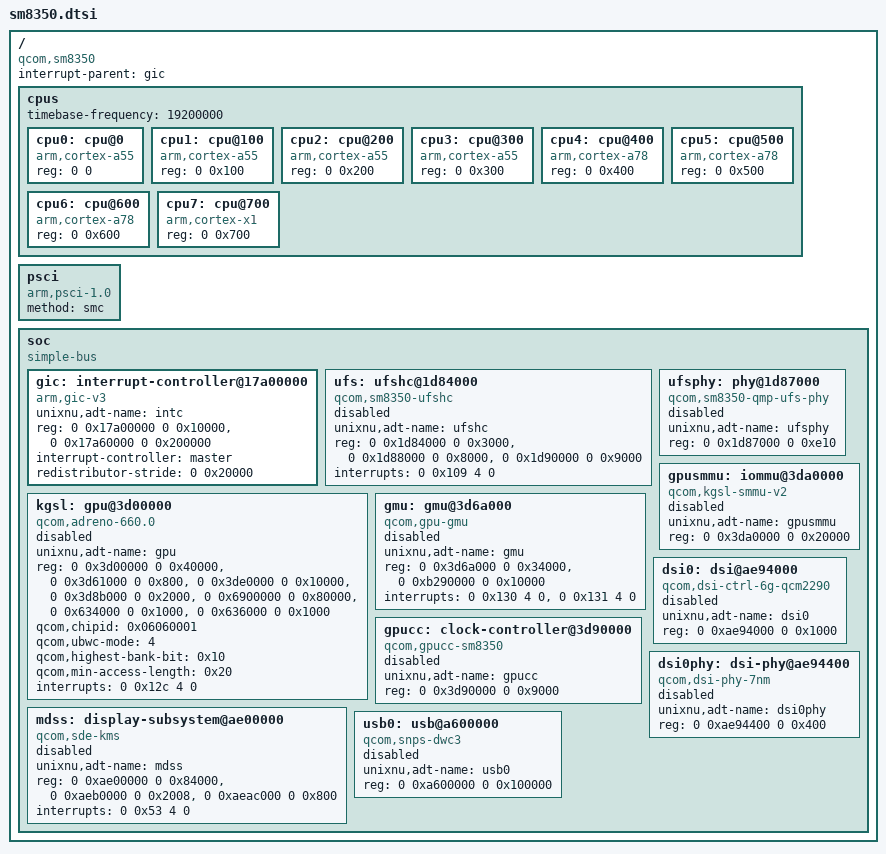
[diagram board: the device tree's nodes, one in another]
// SPDX-License-Identifier: BSD-3-Clause
// Qualcomm SM8350 (lahaina) shared hardware description.
//
// Every value below was cross-checked against the live firmware FDT of a
// Redmi K40 Pro (haydn) extracted on 2026-11-12:
//   /sys/firmware/fdt (799754 bytes) -> UniXNU-haydn/docs/haydn-fdt.dts
// and against the live /sys/bus/platform/devices listing of the same phone.
// The comment above each node names the line it came from.
/ {
    compatible = "qcom,sm8350";
    #address-cells = <2>;
    #size-cells = <2>;
    interrupt-parent = <&gic>;

    cpus {
        #address-cells = <2>;
        #size-cells = <0>;
        // 19.2 MHz always-on XO; GICv3 timer, see the gic node below.
        timebase-frequency = <19200000>;
        cpu0: cpu@0 { device_type = "cpu"; compatible = "arm,cortex-a55"; reg = <0 0>; };
        cpu1: cpu@100 { device_type = "cpu"; compatible = "arm,cortex-a55"; reg = <0 0x100>; };
        cpu2: cpu@200 { device_type = "cpu"; compatible = "arm,cortex-a55"; reg = <0 0x200>; };
        cpu3: cpu@300 { device_type = "cpu"; compatible = "arm,cortex-a55"; reg = <0 0x300>; };
        cpu4: cpu@400 { device_type = "cpu"; compatible = "arm,cortex-a78"; reg = <0 0x400>; };
        cpu5: cpu@500 { device_type = "cpu"; compatible = "arm,cortex-a78"; reg = <0 0x500>; };
        cpu6: cpu@600 { device_type = "cpu"; compatible = "arm,cortex-a78"; reg = <0 0x600>; };
        cpu7: cpu@700 { device_type = "cpu"; compatible = "arm,cortex-x1"; reg = <0 0x700>; };
    };

    psci { compatible = "arm,psci-1.0"; method = "smc"; };

    soc {
        compatible = "simple-bus";
        #address-cells = <2>;
        #size-cells = <2>;
        ranges;

        // haydn-fdt.dts interrupt-controller@17a00000. The redistributor
        // region is 0x200000 with a 0x20000 stride, and the ADT encoder wants
        // 4 interrupt cells on this SoC.
        gic: interrupt-controller@17a00000 {
            compatible = "arm,gic-v3";
            unixnu,adt-name = "intc";
            reg = <0 0x17a00000 0 0x10000>, <0 0x17a60000 0 0x200000>;
            #interrupt-cells = <4>;
            #address-cells = <0>;
            interrupt-controller = "master";
            redistributor-stride = <0 0x20000>;
        };

        // ---- Storage ------------------------------------------------------
        // haydn-fdt.dts ufshc@1d84000: reg = <0x1d84000 0x3000 0x1d88000 0x8000
        // 0x1d90000 0x9000>, names ufs_mem / ufs_ice / ufs_ice_hwkm, five
        // interrupt cells at SPI 0x109.
        ufs: ufshc@1d84000 {
            compatible = "qcom,sm8350-ufshc";
            unixnu,adt-name = "ufshc";
            reg = <0 0x1d84000 0 0x3000>,
                  <0 0x1d88000 0 0x8000>,
                  <0 0x1d90000 0 0x9000>;
            reg-names = "ufs_mem", "ufs_ice", "ufs_ice_hwkm";
            interrupts = <0 0x109 4 0>;
            status = "disabled";
        };

        // CORRECTED 2026-11-12. This node used to carry reg 0x1d80000, which
        // is not this board's UFS PHY and makes the PHY bring-up touch the
        // wrong registers. The live tree says:
        //   ufsphy_mem@1d87000 { reg = <0x1d87000 0xe10>;
        //                        compatible = "qcom,ufs-phy-qmp-v4-lahaina"; }
        // The live platform listing agrees: 1d87000.ufsphy_mem.
        ufsphy: phy@1d87000 {
            compatible = "qcom,sm8350-qmp-ufs-phy";
            unixnu,adt-name = "ufsphy";
            reg = <0 0x1d87000 0 0xe10>;
            status = "disabled";
        };

        // ---- GPU (Adreno 660v2) -------------------------------------------
        // haydn-fdt.dts qcom,kgsl-3d0@3d00000. chipid 0x06060001 identifies
        // the A660; the seven reg windows are the 3D core, the CX debug block,
        // RSCC, the ISENSE block, QDSS GFX and the two RDPM counters.
        kgsl: gpu@3d00000 {
            compatible = "qcom,adreno-660.0", "qcom,adreno";
            unixnu,adt-name = "gpu";
            reg = <0 0x3d00000 0 0x40000>,
                  <0 0x3d61000 0 0x800>,
                  <0 0x3de0000 0 0x10000>,
                  <0 0x3d8b000 0 0x2000>,
                  <0 0x6900000 0 0x80000>,
                  <0 0x634000 0 0x1000>,
                  <0 0x636000 0 0x1000>;
            reg-names = "kgsl_3d0_reg_memory", "cx_dbgc", "rscc", "isense_cntl",
                        "qdss_gfx", "rdpm_cx", "rdpm_mx";
            // 0x06060001: the A660 device id the vendor tree publishes.
            qcom,chipid = <0x06060001>;
            qcom,ubwc-mode = <4>;
            qcom,highest-bank-bit = <0x10>;
            qcom,min-access-length = <0x20>;
            interrupts = <0 0x12c 4 0>;
            status = "disabled";
        };

        // haydn-fdt.dts qcom,gmu@3d69000: reg = <0x3d6a000 0x34000
        // 0xb290000 0x10000>. Note the node name says 3d69000 while reg says
        // 3d6a000; the reg is what the hardware answers on (live listing:
        // 3d6a000.qcom,gmu). The HFI interrupt is 0x130, the GMU's own 0x131.
        gmu: gmu@3d6a000 {
            compatible = "qcom,gpu-gmu";
            unixnu,adt-name = "gmu";
            reg = <0 0x3d6a000 0 0x34000>,
                  <0 0xb290000 0 0x10000>;
            reg-names = "kgsl_gmu_reg", "kgsl_gmu_pdc_cfg";
            interrupts = <0 0x130 4 0>, <0 0x131 4 0>;
            status = "disabled";
        };

        // haydn-fdt.dts qcom,gpucc@3d90000. The GPU's own clock controller:
        // the same block the Adreno 642L of an SC7280 has, at the same address.
        gpucc: clock-controller@3d90000 {
            compatible = "qcom,gpucc-sm8350";
            unixnu,adt-name = "gpucc";
            reg = <0 0x3d90000 0 0x9000>;
            status = "disabled";
        };

        // haydn-fdt.dts kgsl-smmu@3da0000, with gfx3d_user / gfx3d_lpac /
        // gfx3d_secure as its three translation contexts and the two TBUs at
        // 0x3dc5000 and 0x3dc9000. The GPU's DMA goes through this.
        gpusmmu: iommu@3da0000 {
            compatible = "qcom,kgsl-smmu-v2";
            unixnu,adt-name = "gpusmmu";
            reg = <0 0x3da0000 0 0x20000>;
            #iommu-cells = <3>;
            status = "disabled";
        };

        // ---- Display ------------------------------------------------------
        // haydn-fdt.dts qcom,mdss_mdp@ae00000: mdp 0xae00000+0x84000,
        // vbif 0xaeb0000+0x2008, regdma 0xaeac000+0x800, SPI 0x53.
        mdss: display-subsystem@ae00000 {
            compatible = "qcom,sde-kms";
            unixnu,adt-name = "mdss";
            reg = <0 0xae00000 0 0x84000>,
                  <0 0xaeb0000 0 0x2008>,
                  <0 0xaeac000 0 0x800>;
            reg-names = "mdp_phys", "vbif_phys", "regdma_phys";
            interrupts = <0 0x53 4 0>;
            status = "disabled";
        };

        // The primary DSI controller and its PHY. The panel is
        // qcom,mdss_dsi_k11_38_08_0a_dsc_cmd: 1080x2400, DSC, 60/90/120 Hz.
        dsi0: dsi@ae94000 {
            compatible = "qcom,dsi-ctrl-6g-qcm2290";
            unixnu,adt-name = "dsi0";
            reg = <0 0xae94000 0 0x1000>;
            status = "disabled";
        };

        dsi0phy: dsi-phy@ae94400 {
            compatible = "qcom,dsi-phy-7nm";
            unixnu,adt-name = "dsi0phy";
            reg = <0 0xae94400 0 0x400>;
            status = "disabled";
        };

        // ---- USB ----------------------------------------------------------
        usb0: usb@a600000 {
            compatible = "qcom,snps-dwc3";
            unixnu,adt-name = "usb0";
            reg = <0 0xa600000 0 0x100000>;
            status = "disabled";
        };
    };
};
